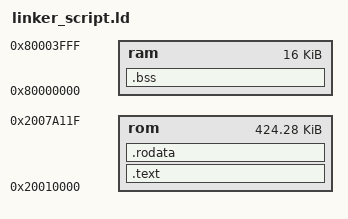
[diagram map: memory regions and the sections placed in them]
OUTPUT_FORMAT("elf32-littleriscv", "elf32-littleriscv", "elf32-littleriscv")
ENTRY(main)
MEMORY
{
    rom : ORIGIN = 0x20010000, LENGTH = 0x6a120
    ram : ORIGIN = 0x80000000, LENGTH = 0x4000
}
SECTIONS
{
    .text : { *(.text*) } > rom
    .rodata : { *(.rodata*) } > rom
    .bss : { *(.bss*) } > ram 
}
